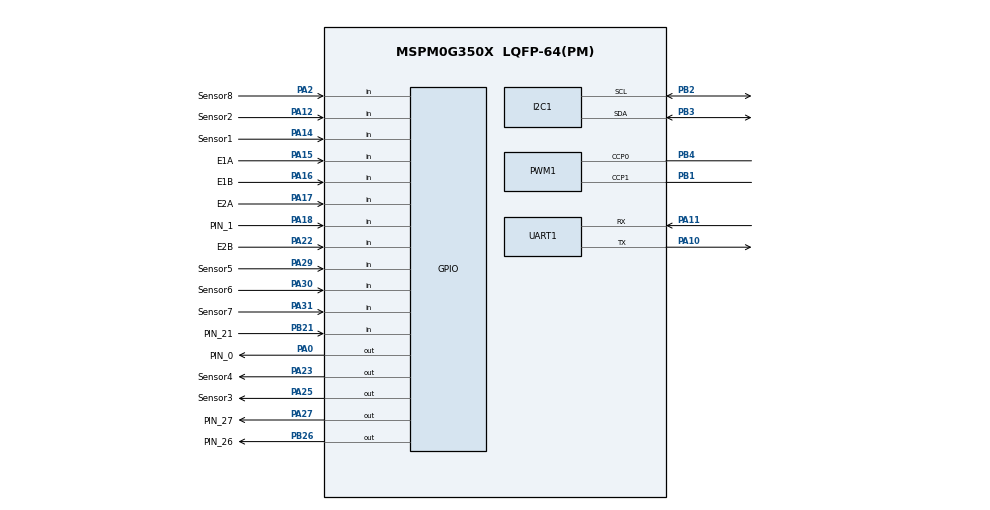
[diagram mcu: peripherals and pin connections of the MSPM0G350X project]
/**
 * @cliArgs --device "MSPM0G350X" --part "Default" --package "LQFP-64(PM)" --product "mspm0_sdk@2.04.00.06"
 * @versions {"tool":"1.23.1+4034"}
 */

/**
 * Import the modules used in this configuration.
 */
const GPIO    = scripting.addModule("/ti/driverlib/GPIO", {}, false);
const GPIO1   = GPIO.addInstance();
const GPIO2   = GPIO.addInstance();
const GPIO3   = GPIO.addInstance();
const GPIO4   = GPIO.addInstance();
const GPIO5   = GPIO.addInstance();
const GPIO6   = GPIO.addInstance();
const GPIO7   = GPIO.addInstance();
const GPIO8   = GPIO.addInstance();
const I2C     = scripting.addModule("/ti/driverlib/I2C", {}, false);
const I2C1    = I2C.addInstance();
const I2C2    = I2C.addInstance();
const PWM     = scripting.addModule("/ti/driverlib/PWM", {}, false);
const PWM1    = PWM.addInstance();
const SYSCTL  = scripting.addModule("/ti/driverlib/SYSCTL");
const SYSTICK = scripting.addModule("/ti/driverlib/SYSTICK");
const TIMER   = scripting.addModule("/ti/driverlib/TIMER", {}, false);
const TIMER1  = TIMER.addInstance();
const UART    = scripting.addModule("/ti/driverlib/UART", {}, false);
const UART1   = UART.addInstance();

/**
 * Write custom configuration values to the imported modules.
 */
const gate7  = system.clockTree["MFCLKGATE"];
gate7.enable = true;

GPIO1.port                               = "PORTA";
GPIO1.$name                              = "RGB_GREEN";
GPIO1.associatedPins[0].$name            = "PIN_0";
GPIO1.associatedPins[0].internalResistor = "PULL_DOWN";
GPIO1.associatedPins[0].assignedPin      = "0";
GPIO1.associatedPins[0].pin.$assign      = "PA0";

const Board = scripting.addModule("/ti/driverlib/Board", {}, false);

GPIO2.port                               = "PORTB";
GPIO2.$name                              = "KEY_MODE";
GPIO2.associatedPins[0].direction        = "INPUT";
GPIO2.associatedPins[0].polarity         = "RISE";
GPIO2.associatedPins[0].$name            = "PIN_21";
GPIO2.associatedPins[0].assignedPin      = "21";
GPIO2.associatedPins[0].ioStructure      = "SD";
GPIO2.associatedPins[0].internalResistor = "PULL_UP";
GPIO2.associatedPins[0].pin.$assign      = "PB21";

GPIO3.$name                               = "ENCODERA";
GPIO3.port                                = "PORTA";
GPIO3.associatedPins.create(2);
GPIO3.associatedPins[0].direction         = "INPUT";
GPIO3.associatedPins[0].interruptEn       = true;
GPIO3.associatedPins[0].polarity          = "RISE";
GPIO3.associatedPins[0].interruptPriority = "0";
GPIO3.associatedPins[0].$name             = "E1A";
GPIO3.associatedPins[0].assignedPin       = "15";
GPIO3.associatedPins[0].pin.$assign       = "PA15";
GPIO3.associatedPins[1].direction         = "INPUT";
GPIO3.associatedPins[1].interruptEn       = true;
GPIO3.associatedPins[1].polarity          = "RISE";
GPIO3.associatedPins[1].interruptPriority = "0";
GPIO3.associatedPins[1].$name             = "E1B";
GPIO3.associatedPins[1].assignedPin       = "16";
GPIO3.associatedPins[1].pin.$assign       = "PA16";

GPIO4.$name                         = "RGB_Red";
GPIO4.port                          = "PORTB";
GPIO4.associatedPins[0].$name       = "PIN_26";
GPIO4.associatedPins[0].assignedPin = "26";
GPIO4.associatedPins[0].pin.$assign = "PB26";

GPIO5.$name                               = "ENCODERB";
GPIO5.port                                = "PORTA";
GPIO5.associatedPins.create(2);
GPIO5.associatedPins[0].$name             = "E2A";
GPIO5.associatedPins[0].direction         = "INPUT";
GPIO5.associatedPins[0].assignedPin       = "17";
GPIO5.associatedPins[0].interruptEn       = true;
GPIO5.associatedPins[0].polarity          = "RISE";
GPIO5.associatedPins[0].interruptPriority = "0";
GPIO5.associatedPins[0].pin.$assign       = "PA17";
GPIO5.associatedPins[1].$name             = "E2B";
GPIO5.associatedPins[1].direction         = "INPUT";
GPIO5.associatedPins[1].assignedPin       = "22";
GPIO5.associatedPins[1].interruptEn       = true;
GPIO5.associatedPins[1].polarity          = "RISE";
GPIO5.associatedPins[1].interruptPriority = "0";
GPIO5.associatedPins[1].pin.$assign       = "PA22";

GPIO6.$name                              = "Sensor";
GPIO6.port                               = "PORTA";
GPIO6.associatedPins.create(8);
GPIO6.associatedPins[0].$name            = "Sensor5";
GPIO6.associatedPins[0].direction        = "INPUT";
GPIO6.associatedPins[0].assignedPin      = "29";
GPIO6.associatedPins[0].internalResistor = "PULL_UP";
GPIO6.associatedPins[0].pin.$assign      = "PA29";
GPIO6.associatedPins[1].$name            = "Sensor6";
GPIO6.associatedPins[1].direction        = "INPUT";
GPIO6.associatedPins[1].assignedPin      = "30";
GPIO6.associatedPins[1].internalResistor = "PULL_UP";
GPIO6.associatedPins[1].pin.$assign      = "PA30";
GPIO6.associatedPins[2].$name            = "Sensor7";
GPIO6.associatedPins[2].direction        = "INPUT";
GPIO6.associatedPins[2].assignedPin      = "31";
GPIO6.associatedPins[2].internalResistor = "PULL_UP";
GPIO6.associatedPins[2].pin.$assign      = "PA31";
GPIO6.associatedPins[3].$name            = "Sensor8";
GPIO6.associatedPins[3].direction        = "INPUT";
GPIO6.associatedPins[3].assignedPin      = "2";
GPIO6.associatedPins[3].internalResistor = "PULL_UP";
GPIO6.associatedPins[3].pin.$assign      = "PA2";
GPIO6.associatedPins[4].direction        = "INPUT";
GPIO6.associatedPins[4].$name            = "Sensor1";
GPIO6.associatedPins[4].internalResistor = "PULL_UP";
GPIO6.associatedPins[4].pin.$assign      = "PA14";
GPIO6.associatedPins[5].direction        = "INPUT";
GPIO6.associatedPins[5].$name            = "Sensor2";
GPIO6.associatedPins[5].internalResistor = "PULL_UP";
GPIO6.associatedPins[5].pin.$assign      = "PA12";
GPIO6.associatedPins[6].$name            = "Sensor3";
GPIO6.associatedPins[6].internalResistor = "PULL_UP";
GPIO6.associatedPins[6].pin.$assign      = "PA25";
GPIO6.associatedPins[7].$name            = "Sensor4";
GPIO6.associatedPins[7].internalResistor = "PULL_UP";
GPIO6.associatedPins[7].pin.$assign      = "PA23";

GPIO7.$name                         = "KEY_START";
GPIO7.port                          = "PORTA";
GPIO7.associatedPins[0].$name       = "PIN_1";
GPIO7.associatedPins[0].direction   = "INPUT";
GPIO7.associatedPins[0].pin.$assign = "PA18";

GPIO8.$name                              = "BEEF";
GPIO8.port                               = "PORTA";
GPIO8.associatedPins[0].$name            = "PIN_27";
GPIO8.associatedPins[0].assignedPin      = "27";
GPIO8.associatedPins[0].initialValue     = "SET";
GPIO8.associatedPins[0].internalResistor = "PULL_DOWN";
GPIO8.associatedPins[0].pin.$assign      = "PA27";

I2C1.basicEnableController             = true;
I2C1.basicControllerStandardBusSpeed   = "Fast";
I2C1.$name                             = "I2C_MPU6050";
I2C1.intController                     = ["ARBITRATION_LOST","NACK","RXFIFO_TRIGGER","RX_DONE","TX_DONE"];
I2C1.peripheral.$assign                = "I2C1";
I2C1.peripheral.sdaPin.$assign         = "PB3";
I2C1.peripheral.sclPin.$assign         = "PB2";
I2C1.sdaPinConfig.hideOutputInversion  = scripting.forceWrite(false);
I2C1.sdaPinConfig.onlyInternalResistor = scripting.forceWrite(false);
I2C1.sdaPinConfig.passedPeripheralType = scripting.forceWrite("Digital");
I2C1.sdaPinConfig.$name                = "ti_driverlib_gpio_GPIOPinGeneric6";
I2C1.sclPinConfig.hideOutputInversion  = scripting.forceWrite(false);
I2C1.sclPinConfig.onlyInternalResistor = scripting.forceWrite(false);
I2C1.sclPinConfig.passedPeripheralType = scripting.forceWrite("Digital");
I2C1.sclPinConfig.$name                = "ti_driverlib_gpio_GPIOPinGeneric7";

I2C2.basicEnableController             = true;
I2C2.basicControllerStandardBusSpeed   = "Fast";
I2C2.$name                             = "I2C_OLED";
I2C2.sdaPinConfig.hideOutputInversion  = scripting.forceWrite(false);
I2C2.sdaPinConfig.onlyInternalResistor = scripting.forceWrite(false);
I2C2.sdaPinConfig.passedPeripheralType = scripting.forceWrite("Digital");
I2C2.sdaPinConfig.$name                = "ti_driverlib_gpio_GPIOPinGeneric8";
I2C2.sclPinConfig.hideOutputInversion  = scripting.forceWrite(false);
I2C2.sclPinConfig.onlyInternalResistor = scripting.forceWrite(false);
I2C2.sclPinConfig.passedPeripheralType = scripting.forceWrite("Digital");
I2C2.sclPinConfig.$name                = "ti_driverlib_gpio_GPIOPinGeneric9";

PWM1.$name                      = "PWM_0";
PWM1.timerStartTimer            = true;
PWM1.pwmMode                    = "EDGE_ALIGN_UP";
PWM1.timerCount                 = 3600;
PWM1.peripheral.$assign         = "TIMA1";
PWM1.peripheral.ccp0Pin.$assign = "PB4";
PWM1.peripheral.ccp1Pin.$assign = "PB1";
PWM1.PWM_CHANNEL_0.$name        = "ti_driverlib_pwm_PWMTimerCC0";
PWM1.PWM_CHANNEL_1.$name        = "ti_driverlib_pwm_PWMTimerCC1";
PWM1.ccp0PinConfig.$name        = "ti_driverlib_gpio_GPIOPinGeneric2";
PWM1.ccp1PinConfig.$name        = "ti_driverlib_gpio_GPIOPinGeneric3";

SYSCTL.forceDefaultClkConfig = true;
SYSCTL.clockTreeEn           = true;

SYSTICK.periodEnable      = true;
SYSTICK.systickEnable     = true;
SYSTICK.interruptPriority = "0";
SYSTICK.period            = 32;

TIMER1.$name            = "TIMER_0";
TIMER1.timerClkDiv      = 8;
TIMER1.timerClkPrescale = 200;
TIMER1.timerStartTimer  = true;
TIMER1.timerMode        = "PERIODIC";
TIMER1.interrupts       = ["ZERO"];
TIMER1.timerPeriod      = "50 ms";

UART1.enabledInterrupts                = ["RX"];
UART1.$name                            = "UART_DM_IMU";
UART1.targetBaudRate                   = 921600;
UART1.peripheral.$assign               = "UART0";
UART1.peripheral.rxPin.$assign         = "PA11";
UART1.peripheral.txPin.$assign         = "PA10";
UART1.txPinConfig.direction            = scripting.forceWrite("OUTPUT");
UART1.txPinConfig.hideOutputInversion  = scripting.forceWrite(false);
UART1.txPinConfig.onlyInternalResistor = scripting.forceWrite(false);
UART1.txPinConfig.passedPeripheralType = scripting.forceWrite("Digital");
UART1.txPinConfig.$name                = "ti_driverlib_gpio_GPIOPinGeneric0";
UART1.rxPinConfig.hideOutputInversion  = scripting.forceWrite(false);
UART1.rxPinConfig.onlyInternalResistor = scripting.forceWrite(false);
UART1.rxPinConfig.passedPeripheralType = scripting.forceWrite("Digital");
UART1.rxPinConfig.$name                = "ti_driverlib_gpio_GPIOPinGeneric1";

/**
 * Pinmux solution for unlocked pins/peripherals. This ensures that minor changes to the automatic solver in a future
 * version of the tool will not impact the pinmux you originally saw.  These lines can be completely deleted in order to
 * re-solve from scratch.
 */
Board.peripheral.$suggestSolution          = "DEBUGSS";
Board.peripheral.swclkPin.$suggestSolution = "PA20";
Board.peripheral.swdioPin.$suggestSolution = "PA19";
I2C2.peripheral.$suggestSolution           = "I2C0";
I2C2.peripheral.sdaPin.$suggestSolution    = "PA28";
I2C2.peripheral.sclPin.$suggestSolution    = "PA1";
TIMER1.peripheral.$suggestSolution         = "TIMA0";
